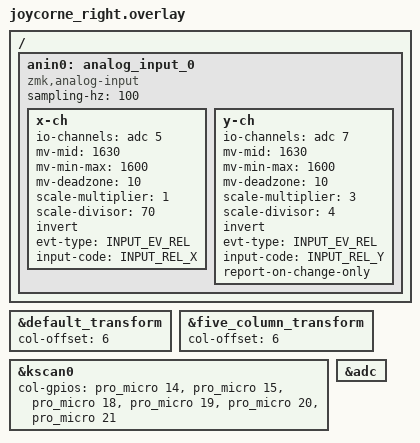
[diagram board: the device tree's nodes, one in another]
/*
 * Copyright (c) 2020 Pete Johanson
 *
 * SPDX-License-Identifier: MIT
 */

#include "joycorne.dtsi"

&default_transform {
    col-offset = <6>;
};

&five_column_transform {
    col-offset = <6>;
};

&kscan0 {
    col-gpios
        = <&pro_micro 14 GPIO_ACTIVE_HIGH>
        , <&pro_micro 15 GPIO_ACTIVE_HIGH>
        , <&pro_micro 18 GPIO_ACTIVE_HIGH>
        , <&pro_micro 19 GPIO_ACTIVE_HIGH>
        , <&pro_micro 20 GPIO_ACTIVE_HIGH>
        , <&pro_micro 21 GPIO_ACTIVE_HIGH>
        ;
};

#include <zephyr/dt-bindings/input/input-event-codes.h>
/* Reference: https://docs.zephyrprzoject.org/apidoc/latest/group__input__events.html */

&adc {
	status = "okay";
};

/ {
	anin0: analog_input_0 {
		compatible = "zmk,analog-input";
		sampling-hz = <100>;
		x-ch {
			io-channels = <&adc 5>;
			mv-mid = <1630>;
			mv-min-max = <1600>;
			mv-deadzone = <10>;
			scale-multiplier = <1>;
			scale-divisor = <70>;
			invert;
			evt-type = <INPUT_EV_REL>;
			input-code = <INPUT_REL_X>;
		};
		y-ch {
			io-channels = <&adc 7>;
			mv-mid = <1630>;
			mv-min-max = <1600>;
			mv-deadzone = <10>;
			scale-multiplier = <3>;
			scale-divisor = <4>;
			invert;
			evt-type = <INPUT_EV_REL>;
			input-code = <INPUT_REL_Y>;

			/* enable report mdoe for gamepad axix or knob */
			/* to only call input_report on quantquantized value is updated */
			report-on-change-only;

		};
	};
};
